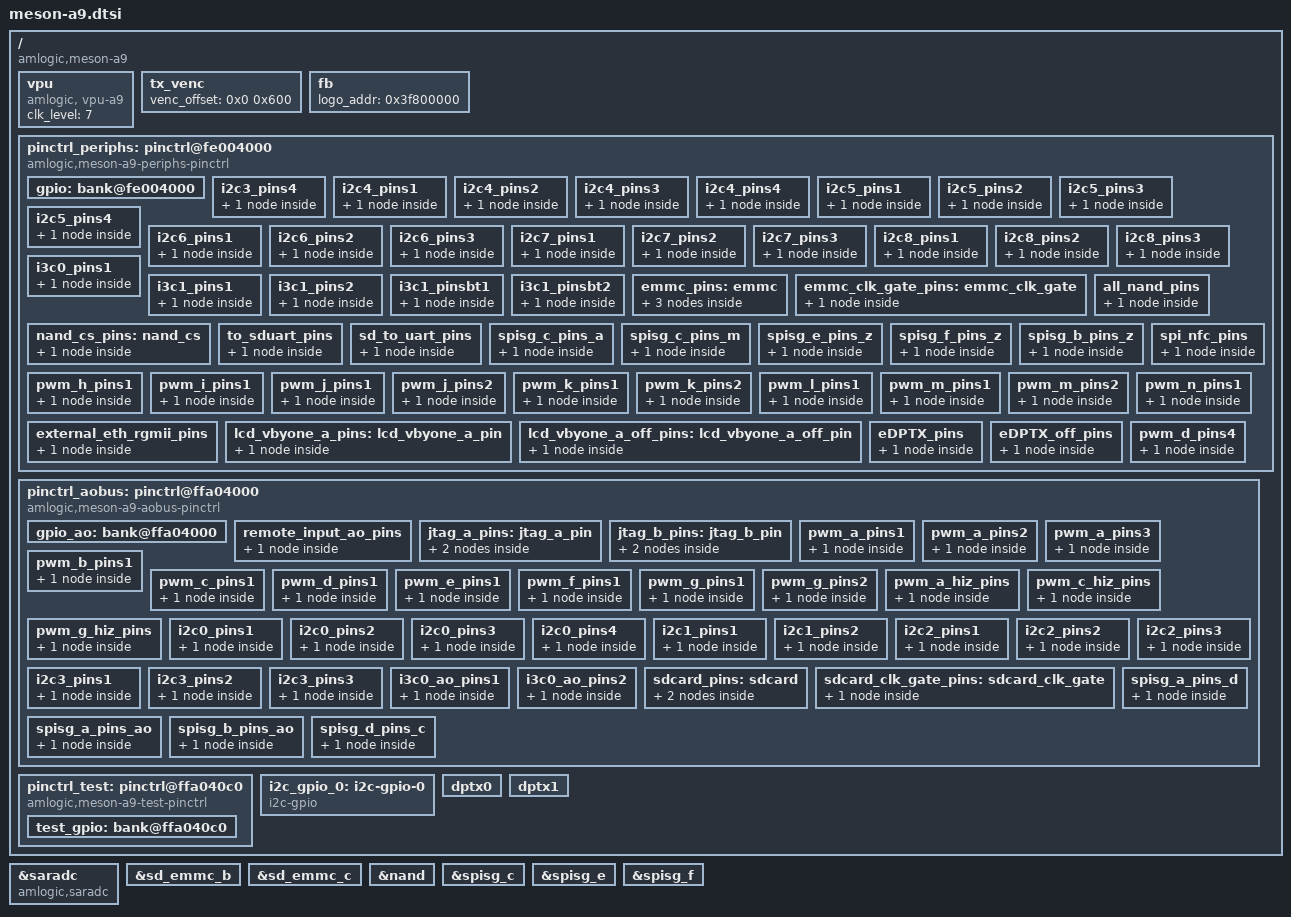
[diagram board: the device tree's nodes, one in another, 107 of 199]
// SPDX-License-Identifier: (GPL-2.0+ OR MIT)
/*
 * Copyright (c) 2019 Amlogic, Inc. All rights reserved.
 */

#include "amlogic/meson-a9-series.dtsi"
#include <dt-bindings/amlogic/gpio/meson-a9-gpio.h>
#include <dt-bindings/reset/amlogic,meson-gxbb-reset.h>
#include <dt-bindings/amlogic/pwm/pwm.h>
#include <dt-bindings/amlogic/pwm/meson.h>

/ {
	compatible = "amlogic,meson-a9";

	vpu: vpu {
		compatible = "amlogic, vpu-a9";
		status = "okay";
		/*clocks = <&clkc CLKID_VAPB>,
		 *	<&clkc CLKID_SYS_VPU_INTR>,
		 *	<&clkc CLKID_VPU_0>,
		 *	<&clkc CLKID_VPU_1>,
		 *	<&clkc CLKID_VPU>;
		 *clock-names = "vapb_clk",
		 *	"vpu_intr_gate",
		 *	"vpu_clk0",
		 *	"vpu_clk1",
		 *	"vpu_clk";
		 */
		clk_level = <7>;
		/* 0: 100.0M    1: 166.7M    2: 200.0M    3: 250.0M */
		/* 4: 333.3M    5: 400.0M    6: 500.0M    7: 666.7M */
	};

	tx_venc: tx_venc {
		venc_offset = <0x0 0x600>;
	};

	fb {
		status = "okay";
		logo_addr = "0x3f800000";
	};

	pinctrl_periphs: pinctrl@fe004000 {
		compatible = "amlogic,meson-a9-periphs-pinctrl";
		#address-cells = <2>;
		#size-cells = <2>;
		ranges;

		gpio: bank@fe004000 {
			reg = <0x0 0xfe004000 0x0 0x004c>,
			      <0x0 0xfe0040c0 0x0 0x02cc>;
			reg-names = "mux", "gpio";
			gpio-controller;
			#gpio-cells = <2>;
			gpio-ranges = <&pinctrl_periphs 0 0 96>;
		};
	};

	pinctrl_aobus: pinctrl@ffa04000 {
		compatible = "amlogic,meson-a9-aobus-pinctrl";
		#address-cells = <2>;
		#size-cells = <2>;
		ranges;

		gpio_ao: bank@ffa04000 {
			reg = <0x0 0xffa04000 0x0 0x0014>,
			      <0x0 0xffa0401c 0x0 0x0064>;
			reg-names = "mux", "gpio";
			gpio-controller;
			#gpio-cells = <2>;
			gpio-ranges = <&pinctrl_aobus 0 0 38>;
		};
	};

	pinctrl_test: pinctrl@ffa040c0 {
		compatible = "amlogic,meson-a9-test-pinctrl";
		#address-cells = <2>;
		#size-cells = <2>;
		ranges;

		test_gpio: bank@ffa040c0 {
			reg = <0x0 0xffa040c0 0x0 0x0020>;
			reg-names = "gpio";
			gpio-controller;
			#gpio-cells = <2>;
			gpio-ranges = <&pinctrl_test 0 0 1>;
		};
	};

	i2c_gpio_0: i2c-gpio-0 {
		#address-cells = <1>;
		#size-cells = <0>;

		compatible = "i2c-gpio";
		status = "okay";
		//gpios = <&gpio GPIOH_0 GPIO_ACTIVE_HIGH>, /* SDA */
		//	<&gpio GPIOH_1 GPIO_ACTIVE_HIGH>; /* CLK */

		i2c-gpio,delay-us = <5>;
		is_odpin = <1>;
	};

	/* dptx core */
	dptx0: dptx0 {
		dev_index = <0>;
		is_edp = <0>;
		ext_edptx_en = <0>;
		/*
		 * the sequence is as below and should match kernel
		 * dptx
		 * sys_ctrl
		 * ana_ctrl
		 * pwr_ctrl
		 * reset_ctrl
		 * clk_ctrl
		 * vpu_ctrl
		 * pad_ctrl
		 */
		reg = <0xFE484000
			0xFE010000
			0xFE016000
			0xFE00C000
			0xFE002000
			0xFE000000
			0xFF500000
			0xFE004000>;
	};
	/* edptx core */
	dptx1: dptx1 {
		dev_index = <1>;
		is_edp = <1>;
		ext_edptx_en = <1>;
		/*
		 * the sequence is as below and should match kernel
		 * dptx
		 * sys_ctrl
		 * ana_ctrl
		 * pwr_ctrl
		 * reset_ctrl
		 * clk_ctrl
		 * vpu_ctrl
		 * pad_ctrl
		 */
		reg = <0xFE074000
			0xFE010000
			0xFE016000
			0xFE00C000
			0xFE002000
			0xFE000000
			0xFF500000
			0xFE004000>;
	};
};

&saradc {
	compatible = "amlogic,saradc", "amlogic,a9-saradc";
	clocks = <&xtal>,
		 <&clkc CLKID_SAR_ADC_SEL>,
		 <&clkc CLKID_SAR_ADC_DIV>,
		 <&clkc CLKID_SAR_ADC>;
	clock-names = "src", "mux", "div", "gate";
};

&sd_emmc_b {
        clocks = <&clkc CLKID_SD_EMMC_B_SEL>,
			<&clkc CLKID_SD_EMMC_B_DIV>,
                        <&clkc CLKID_SD_EMMC_B>,
                        <&clkc CLKID_FCLK_DIV2>,
			<&xtal>;
                        clock-names = "mux", "div", "gate", "clkin", "xtal";
};

&sd_emmc_c {
	 clocks = <&clkc CLKID_SD_EMMC_C_SEL>,
			<&clkc CLKID_SD_EMMC_C_DIV>,
			<&clkc CLKID_SD_EMMC_C>,
			<&clkc CLKID_GP0_PLL>,
			//<&clkc CLKID_FCLK_DIV2>,
			<&xtal>;
			clock-names = "mux", "div", "gate", "clkin", "xtal";
			assigned-clocks = <&clkc CLKID_GP0_PLL>;
			assigned-clock-rates = <1152000000>;
};

&nand {
	clocks = <&clkc CLKID_SD_EMMC_C_SEL>,
			<&clkc CLKID_SD_EMMC_C_DIV>,
			<&clkc CLKID_SD_EMMC_C>,
			<&clkc CLKID_FCLK_DIV2>,
			<&xtal>;
	clock-names = "mux", "div", "gate", "fdiv2", "xtal";
};

&spisg_c {
	clocks = <&clkc CLKID_SPISG_0_DIV>, <&clkc CLKID_SPISG_0>;
	clock-names = "spi_clk", "sys_clk";
	assigned-clocks = <&clkc CLKID_SPISG_0_SEL>, <&clkc CLKID_SPISG_0_DIV>;
	assigned-clock-parents = <&clkc CLKID_FCLK_DIV2>;
	assigned-clock-rates = <0>, <500000000>;
};

&spisg_e {
	clocks = <&clkc CLKID_SPISG_1_DIV>, <&clkc CLKID_SPISG_1>;
	clock-names = "spi_clk", "sys_clk";
	assigned-clocks = <&clkc CLKID_SPISG_1_SEL>, <&clkc CLKID_SPISG_1_DIV>;
	assigned-clock-parents = <&clkc CLKID_FCLK_DIV2>;
	assigned-clock-rates = <0>, <500000000>;
};

&spisg_f {
	clocks = <&clkc CLKID_SPISG_2_DIV>, <&clkc CLKID_SPISG_2>;
	clock-names = "spi_clk", "sys_clk";
	assigned-clocks = <&clkc CLKID_SPISG_2_SEL>, <&clkc CLKID_SPISG_2_DIV>;
	assigned-clock-parents = <&clkc CLKID_FCLK_DIV2>;
	assigned-clock-rates = <0>, <500000000>;
};

&pinctrl_periphs {
	i2c3_pins4:i2c3_pins4 {
		mux {
			groups = "i2c_d_sda",
				"i2c_d_scl";
			function = "i2c_d";
			bias-disable;
		};
	};

	i2c4_pins1:i2c4_pins1 {
		mux {
			groups = "i2c_e_sda",
				"i2c_e_scl";
			function = "i2c_e";
			drive-strength = <3>;
			bias-disable;
		};
	};

	i2c4_pins2:i2c4_pins2 {
		mux {
			groups = "i2c_e_scl_m",
				"i2c_e_sda_m";
			function = "i2c_e";
			drive-strength = <3>;
			bias-disable;
		};
	};

	i2c4_pins3:i2c4_pins3 {
		mux {
			groups = "i2c_e_scl_y",
				"i2c_e_sda_y";
			function = "i2c_e";
			drive-strength = <3>;
			bias-disable;
		};
	};

	i2c4_pins4:i2c4_pins4 {
		mux {
			groups = "i2c_e_scl_z",
				"i2c_e_sda_z";
			function = "i2c_e";
			drive-strength = <3>;
			bias-disable;
		};
	};

	i2c5_pins1:i2c5_pins1 {
		mux {
			groups = "i2c_f_scl",
				"i2c_f_sda";
			function = "i2c_f";
			drive-strength = <3>;
			bias-disable;
		};
	};

	i2c5_pins2:i2c5_pins2 {
		mux {
			groups = "i2c_f_scl_h",
				"i2c_f_sda_h";
			function = "i2c_f";
			drive-strength = <3>;
			bias-disable;
		};
	};

	i2c5_pins3:i2c5_pins3 {
		mux {
			groups = "i2c_f_sda_cc",
				"i2c_f_scl_cc";
			function = "i2c_f";
			drive-strength = <3>;
			bias-disable;
		};
	};

	i2c5_pins4:i2c5_pins4 {
		mux {
			groups = "i2c_f_scl_m",
				"i2c_f_sda_m";
			function = "i2c_f";
			drive-strength = <3>;
			bias-disable;
		};
	};

	i2c6_pins1:i2c6_pins1 {
		mux {
			groups = "i2c_g_scl",
				"i2c_g_sda";
			function = "i2c_g";
			drive-strength = <3>;
			bias-disable;
		};
	};

	i2c6_pins2:i2c6_pins2 {
		mux {
			groups = "i2c_g_scl_m",
				"i2c_g_sda_m";
			function = "i2c_g";
			drive-strength = <3>;
			bias-disable;
		};
	};

	i2c6_pins3:i2c6_pins3 {
		mux {
			groups = "i2c_g_scl_z",
				"i2c_g_sda_z";
			function = "i2c_g";
			drive-strength = <3>;
			bias-disable;
		};
	};

	i2c7_pins1:i2c7_pins1 {
		mux {
			groups = "i2c_h_scl",
				"i2c_h_sda";
			function = "i2c_h";
			drive-strength = <3>;
			bias-disable;
		};
	};

	i2c7_pins2:i2c7_pins2 {
		mux {
			groups = "i2c_h_scl_m",
				"i2c_h_sda_m";
			function = "i2c_h";
			drive-strength = <3>;
			bias-disable;
		};
	};

	i2c7_pins3:i2c7_pins3 {
		mux {
			groups = "i2c_h_scl_z",
				"i2c_h_sda_z";
			function = "i2c_h";
			drive-strength = <3>;
			bias-disable;
		};
	};

	i2c8_pins1:i2c8_pins1 {
		mux {
			groups = "i2c_i_scl",
				"i2c_i_sda";
			function = "i2c_i";
			drive-strength = <3>;
			bias-disable;
		};
	};

	i2c8_pins2:i2c8_pins2 {
		mux {
			groups = "i2c_i_scl_a",
				"i2c_i_sda_a";
			function = "i2c_i";
			drive-strength = <3>;
			bias-disable;
		};
	};

	i2c8_pins3:i2c8_pins3 {
		mux {
			groups = "i2c_i_scl_y",
				"i2c_i_sda_y";
			function = "i2c_i";
			drive-strength = <3>;
			bias-disable;
		};
	};

	i3c0_pins1:i3c0_pins1 {
		mux {
			groups = "i3c_a_scl",
				"i3c_a_sda";
			function = "i3c_b";
			bias-disable;
		};
	};

	i3c1_pins1:i3c1_pins1 {
		mux {
			groups = "i3c_b_scl",
				"i3c_b_sda_d0";
			function = "i3c_b";
			bias-disable;
			// drive-strength-microamp = <2500>;
		};
	};

	i3c1_pins2:i3c1_pins2 {
		mux {
			groups = "i3c_b_scl_a",
				"i3c_b_sda_d0_a";
			function = "i3c_b";
			bias-disable;
		};
	};

	i3c1_pinsbt1:i3c1_pinsbt1 {
		mux {
			groups = "i3c_b_scl",
				"i3c_b_sda_d0",
				"i3c_b_sda_d1",
				"i3c_b_sda_d2",
				"i3c_b_sda_d3";
			function = "i3c_b";
			bias-disable;
		};
	};

	i3c1_pinsbt2:i3c1_pinsbt2 {
		mux {
			groups = "i3c_b_scl_a",
				"i3c_b_sda_d0_a",
				"i3c_b_sda_d1_a",
				"i3c_b_sda_d2_a",
				"i3c_b_sda_d3_a";
			function = "i3c_b";
			bias-disable;
		};
	};

	emmc_pins: emmc {
		mux {
			groups = "emmc_d0",
				"emmc_d1",
				"emmc_d2",
				"emmc_d3",
				"emmc_d4",
				"emmc_d5",
				"emmc_d6",
				"emmc_d7",
				"emmc_clk",
				"emmc_cmd";
			function = "emmc";
			bias-pull-up;
			input-enable;
		};
		mux1 {
			groups = "emmc_ds";
			function = "emmc";
			input-enable;
			bias-pull-down;
		};
		mux2 {
			groups = "GPIOB_12",
					"GPIOB_13";
			function= "gpio_periphs";
		};
	};

	emmc_clk_gate_pins: emmc_clk_gate {
		mux {
			groups = "emmc_clk";
			function = "emmc";
			bias-pull-down;
		};
	};

	all_nand_pins: all_nand_pins {
		mux {
			groups =  "emmc_d0",
				"emmc_d1",
				"emmc_d2",
				"emmc_d3",
				"emmc_d4",
				"emmc_d5",
				"emmc_d6",
				"emmc_d7",
				"nand_ce0",
				"nand_ale",
				"nand_cle",
				"nand_wen_clk",
				"nand_ren_wr";
			function = "nand";
			input-enable;
		};
	};

	nand_cs_pins: nand_cs {
		mux {
			groups = "nand_ce0";
			function = "nand";
		};
	};

	to_sduart_pins: to_sduart_pins{
		mux {
			groups = "uart_b_rx_c", "uart_b_tx_c";
			function = "uart_b";
			bias-pull-up;
			input-enable;
		};
	};

	sd_to_uart_pins: sd_to_uart_pins{
		mux {
			groups = "uart_b_rx_d", "uart_b_tx_d";
			function = "uart_b";
			bias-pull-up;
			input-enable;
		};
	};

	spisg_c_pins_a: spisg_c_pins_a {
		mux {
			 /* GPIOA_8/9/11/10 */
			groups = "spi_c_mosi",
				 "spi_c_miso",
				 "spi_c_ss0",
				 "spi_c_sclk";
			function = "spi_c";
			drive-strength-microamp = <3000>;
		};
	};

	spisg_c_pins_m: spisg_c_pins_m {
		mux {
			 /* GPIOM_0/1/3/2 */
			groups = "spi_c_mosi_m",
				 "spi_c_miso_m",
				 "spi_c_ss0_m",
				 "spi_c_sclk_m";
			function = "spi_c";
			drive-strength-microamp = <3000>;
		};
	};

	spisg_e_pins_z: spisg_e_pins_z {
		mux {
			 /* GPIOZ_0/1/3/2 */
			groups = "spi_e_mosi",
				 "spi_e_miso",
				 "spi_e_ss0",
				 "spi_e_sclk";
			function = "spi_e";
			drive-strength-microamp = <3000>;
		};
	};

	spisg_f_pins_z: spisg_f_pins_z {
		mux {
			 /* GPIOZ_4/5/7/6 */
			groups = "spi_f_mosi",
				 "spi_f_miso",
				 "spi_f_ss0",
				 "spi_f_sclk";
			function = "spi_f";
			drive-strength-microamp = <3000>;
		};
	};

	spisg_b_pins_z: spisg_b_pins_z {
		mux {
			 /* GPIOZ_10/11/13/9/8/12 */
			groups = "spi_b_mosi",
				 "spi_b_miso",
				 "spi_b_ss0",
				 "spi_b_ss1",
				 "spi_b_ss2",
				 "spi_b_sclk";
			function = "spi_b";
			drive-strength-microamp = <3000>;
		};
	};

	spi_nfc_pins: spi_nfc_pins {
		mux {
			groups = "spinf_mo_d0",
				 "spinf_mi_d1",
				 "spinf_wp_d2",
				 "spinf_hold_d3",
				 "spinf_d4",
				 "spinf_d5",
				 "spinf_d6",
				 "spinf_d7",
				 "spinf_clk",
				 "spinf_cs0";
			function = "spinf";
			drive-strength = <3>;
		};
	};

	pwm_h_pins1: pwm_h_pins1 {
		mux {
			groups = "pwm_h";
			function = "pwm_h";
		};
	};

	pwm_i_pins1: pwm_i_pins1 {
		mux {
			groups = "pwm_i";
			function = "pwm_i";
		};
	};

	pwm_j_pins1: pwm_j_pins1 {
		mux {
			groups = "pwm_j";
			function = "pwm_j";
		};
	};

	pwm_j_pins2: pwm_j_pins2 {
		mux {
			groups = "pwm_j";
			function = "pwm_j_m";
		};
	};

	pwm_k_pins1: pwm_k_pins1 {
		mux {
			groups = "pwm_k";
			function = "pwm_k";
		};
	};

	pwm_k_pins2: pwm_k_pins2 {
		mux {
			groups = "pwm_k_y";
			function = "pwm_k_m";
		};
	};

	pwm_l_pins1: pwm_l_pins1 {
		mux {
			groups = "pwm_l";
			function = "pwm_l";
		};
	};

	pwm_m_pins1: pwm_m_pins1 {
		mux {
			groups = "pwm_m";
			function = "pwm_m";
		};
	};

	pwm_m_pins2: pwm_m_pins2 {
		mux {
			groups = "pwm_m_y";
			function = "pwm_m_m";
		};
	};

	pwm_n_pins1: pwm_n_pins1 {
		mux {
			groups = "pwm_n";
			function = "pwm_n";
		};
	};

	external_eth_rgmii_pins: external_eth_rgmii_pins {
 		mux {
			groups = "eth_a_mdio_z",
				 "eth_a_mdc_z",
				 "eth_a_rgmii_rx_clk",
				 "eth_a_rx_dv",
				 "eth_a_rxd0",
				 "eth_a_rxd1",
				 "eth_a_txen",
				 "eth_a_txd0",
				 "eth_a_txd1",
				 "eth_a_rxd2_rgmii",
				 "eth_a_rxd3_rgmii",
				 "eth_a_rgmii_tx_clk",
				 "eth_a_txd2_rgmii",
				 "eth_a_txd3_rgmii";
			function = "eth_a";
 			drive-strength = <3>;
 		};
 	};

	lcd_vbyone_a_pins: lcd_vbyone_a_pin {
		mux {
			groups = "vx1_lockn_y","vx1_htpdn_y";
			function = "vx1";
		};
	};

	lcd_vbyone_a_off_pins: lcd_vbyone_a_off_pin {
		mux {
			groups = "GPIOY_7","GPIOY_9";
			function = "gpio_periphs";
			input-enable;
		};
	};

	eDPTX_pins: eDPTX_pins {
		mux {
			groups = "edp_hpd_y";
			function = "edp";
		};
	};

	eDPTX_off_pins: eDPTX_off_pins {
		mux {
			groups = "GPIOY_9";
			function = "gpio_periphs";
			input-enable;
		};
	};

	pwm_d_pins4: pwm_d_pins4 {
		mux {
			groups = "pwm_d_h12";
			function = "pwm_d";
		};
	};
};

&pinctrl_aobus {
	remote_input_ao_pins:remote_input_ao_pins {
		mux {
			groups = "ir_in_ao";
			function = "ir_in_ao";
			bias-disable;
		};
	};

	jtag_a_pins: jtag_a_pin {
		mux {
			groups = "jtag_a_clk_ao",
				 "jtag_a_tms_ao",
				 "jtag_a_tdi_ao",
				 "jtag_a_tdo_ao";
			function = "jtag_a_ao";
		};

		mux-unused {
			groups = "GPIOD_8",
				 "GPIOD_9",
				 "GPIOD_10",
				 "GPIOD_11";
			function = "gpio_periphs";
		};
	};

	jtag_b_pins:jtag_b_pin {
		mux {
			groups = "jtag_b_clk_ao",
				 "jtag_b_tms_ao",
				 "jtag_b_tdi_ao",
				 "jtag_b_tdo_ao";
			function = "jtag_b_ao";
		};

		mux-unused {
			groups = "GPIOC_0",
				 "GPIOC_1",
				 "GPIOC_4",
				 "GPIOC_5";
			function = "gpio_periphs";
		};
	};

	pwm_a_pins1: pwm_a_pins1 {
		mux {
			groups = "pwm_a_ao";
			function = "pwm_a_ao";
		};
	};

	pwm_a_pins2: pwm_a_pins2 {
		mux {
			groups = "pwm_a_ao_ao";
			function = "pwm_a_ao";
		};
	};

	pwm_a_pins3: pwm_a_pins3 {
		mux {
			groups = "pwm_a_ao_ao11";
			function = "pwm_a_ao";
		};
	};

	pwm_b_pins1: pwm_b_pins1 {
		mux {
			groups = "pwm_b_ao";
			function = "pwm_b_ao";
		};
	};

	pwm_c_pins1: pwm_c_pins1 {
		mux {
			groups = "pwm_c_ao";
			function = "pwm_c_ao";
		};
	};

	pwm_d_pins1: pwm_d_pins1 {
		mux {
			groups = "pwm_d_ao";
			function = "pwm_d_ao";
		};
	};

	pwm_e_pins1: pwm_e_pins1 {
		mux {
			groups = "pwm_e_ao";
			function = "pwm_e_ao";
		};
	};

	pwm_f_pins1: pwm_f_pins1 {
		mux {
			groups = "pwm_f_ao";
			function = "pwm_f_ao";
		};
	};

	pwm_g_pins1: pwm_g_pins1 {
		mux {
			groups = "pwm_g_ao";
			function = "pwm_g_ao";
		};
	};

	pwm_g_pins2: pwm_g_pins2 {
		mux {
			groups = "pwm_g_ao_ao";
			function = "pwm_g_ao";
		};
	};

	pwm_a_hiz_pins: pwm_a_hiz_pins {
		mux {
			groups = "pwm_a_hiz_ao";
			function = "pwm_a_ao";
		};
	};

	pwm_c_hiz_pins: pwm_c_hiz_pins {
		mux {
			groups = "pwm_c_hiz_ao";
			function = "pwm_b_ao";
		};
	};

	pwm_g_hiz_pins: pwm_g_hiz_pins {
		mux {
			groups = "pwm_g_hiz_ao";
			function = "pwm_g_ao";
		};
	};

	i2c0_pins1:i2c0_pins1 {
		mux {
			groups = "i2c_a_scl_ao",
				"i2c_a_sda_ao";
			function = "i2c_a_ao";
			drive-strength = <3>;
			bias-disable;
		};
	};

	i2c0_pins2:i2c0_pins2 {
		mux {
			groups = "i2c_a_scl_ao_c",
				"i2c_a_sda_ao_c";
			function = "i2c_a_ao";
			drive-strength = <3>;
			bias-disable;
		};
	};

	i2c0_pins3:i2c0_pins3 {
		mux {
			groups = "i2c_a_scl_ao_d",
				"i2c_a_sda_ao_d";
			function = "i2c_a_ao";
			drive-strength = <3>;
			bias-disable;
		};
	};

	i2c0_pins4:i2c0_pins4 {
		mux {
			groups = "i2c_a_scl_ao_ao",
				"i2c_a_sda_ao_ao";
			function = "i2c_a_ao";
			drive-strength = <3>;
			bias-disable;
		};
	};

	i2c1_pins1:i2c1_pins1 {
		mux {
			groups = "i2c_b_scl_ao",
				"i2c_b_sda_ao";
			function = "i2c_b_ao";
			drive-strength = <3>;
			bias-disable;
		};
	};

	i2c1_pins2:i2c1_pins2 {
		mux {
			groups = "i2c_b_scl_ao_c",
				"i2c_b_sda_ao_c";
			function = "i2c_b_ao";
			drive-strength = <3>;
			bias-disable;
		};
	};

	i2c2_pins1:i2c2_pins1 {
		mux {
			groups = "i2c_c_scl_ao",
				"i2c_c_sda_ao";
			function = "i2c_c_ao";
			drive-strength = <3>;
			bias-disable;
		};
	};

	i2c2_pins2:i2c2_pins2 {
		mux {
			groups = "i2c_c_scl_ao_c",
				"i2c_c_sda_ao_c";
			function = "i2c_c_ao";
			drive-strength = <3>;
			bias-disable;
		};
	};

	i2c2_pins3:i2c2_pins3 {
		mux {
			groups = "i2c_c_scl_ao_ao",
				"i2c_c_scl_ao_ao";
			function = "i2c_c_ao";
			drive-strength = <3>;
			bias-disable;
		};
	};

	i2c3_pins1:i2c3_pins1 {
		mux {
			groups = "i2c_d_scl_ao",
				"i2c_d_sda_ao";
			function = "i2c_d_ao";
			drive-strength = <3>;
			bias-disable;
		};
	};

	i2c3_pins2:i2c3_pins2 {
		mux {
			groups = "i2c_d_scl_ao_ao",
				"i2c_d_scl_ao_ao";
			function = "i2c_d_ao";
			drive-strength = <3>;
			bias-disable;
		};
	};

	i2c3_pins3:i2c3_pins3 {
		mux {
			groups = "i2c_d_scl_ao_ao8",
				"i2c_d_sda_ao_ao9";
			function = "i2c_d_ao";
			drive-strength = <3>;
			bias-disable;
		};
	};

	i3c0_ao_pins1:i3c0_ao_pins1 {
		mux {
			groups = "i3c_a_scl_ao",
				"i3c_a_sda_ao";
			function = "i3c_a";
			bias-disable;
		};
	};

	i3c0_ao_pins2:i3c0_ao_pins2 {
		mux {
			groups = "i3c_a_scl_ao_c",
				"i3c_a_sda_ao_c";
			function = "i3c_a";
			bias-disable;
		};
	};

      sdcard_pins: sdcard {
              mux {
                      groups = "sdcard_d0_ao",
                              "sdcard_d1_ao",
                              "sdcard_d2_ao",
                              "sdcard_d3_ao",
                              "sdcard_cmd_ao";
                      function = "sdcard_ao";
                      bias-pull-up;
                      input-enable;
                      drive-strength = <4>;
              };
              mux1 {
                      groups ="sdcard_clk_ao";
                      function = "sdcard_ao";
                      bias-pull-up;
                      output-high;
                      drive-strength = <4>;
              };
      };

      sdcard_clk_gate_pins: sdcard_clk_gate {
              mux {
                      groups = "sdcard_clk_ao";
                      function = "sdcard_ao";
                      bias-pull-down;
              };
      };

	spisg_a_pins_d: spisg_a_pins_d {
		mux {
			 /* GPIOD_3/4/5/6/7/2 */
			groups = "spi_a_mosi_ao",
				 "spi_a_miso_ao",
				 "spi_a_ss0_ao",
				 "spi_a_ss1_ao",
				 "spi_a_ss2_ao",
				 "spi_a_sclk_ao";
			function = "spi_a_ao";
			drive-strength-microamp = <3000>;
		};
	};

	spisg_a_pins_ao: spisg_a_pins_ao {
		mux {
			 /* GPIOAO_1/2/3/0 */
			groups = "spi_a_mosi_ao_ao",
				 "spi_a_miso_ao_ao",
				 "spi_a_ss0_ao_ao",
				 "spi_a_sclk_ao_ao";
			function = "spi_a_ao";
			drive-strength-microamp = <3000>;
		};
	};

	spisg_b_pins_ao: spisg_b_pins_ao {
		mux {
			 /* GPIOAO_4/5/7/8/9/6 */
			groups = "spi_b_mosi_ao",
				 "spi_b_miso_ao",
				 "spi_b_ss0_ao",
				 "spi_b_ss1_ao",
				 "spi_b_ss2_ao",
				 "spi_b_sclk_ao";
			function = "spi_b_ao";
			drive-strength-microamp = <3000>;
		};
	};

	spisg_d_pins_c: spisg_d_pins_c {
		mux {
			 /* GPIOC_0/1/3/4/5/2 */
			groups = "spi_d_mosi_ao",
				 "spi_d_miso_ao",
				 "spi_d_ss0_ao",
				 "spi_d_ss1_ao",
				 "spi_d_ss2_ao",
				 "spi_d_sclk_ao";
			function = "spi_d_ao";
			drive-strength-microamp = <3000>;
		};
	};
};
